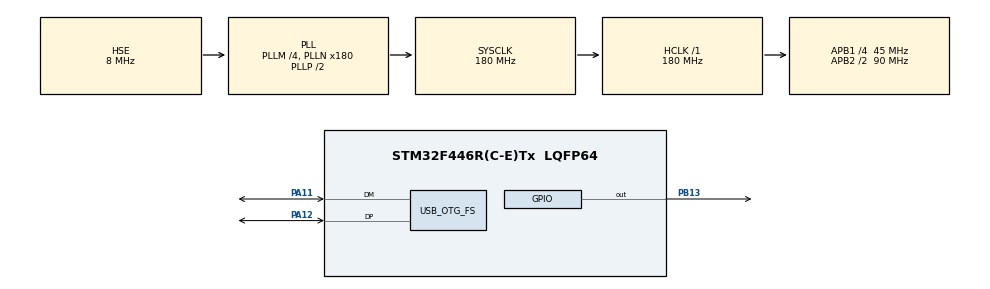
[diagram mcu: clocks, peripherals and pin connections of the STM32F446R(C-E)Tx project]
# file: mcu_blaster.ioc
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Mcu.Family=STM32F4
USB_DEVICE.CLASS_NAME_FS=CDC
USB_DEVICE.USBD_LPM_ENABLED-CDC_FS=0
PH0-OSC_IN.Signal=RCC_OSC_IN
RCC.CortexFreq_Value=180000000
USB_DEVICE.VirtualModeFS=Cdc_FS
USB_DEVICE.PID_CDC_FS=0x6001
PA11.Mode=Device_Only
USB_DEVICE.VirtualMode-CDC_FS=Cdc
RCC.APB1CLKDivider=RCC_HCLK_DIV4
PB13.Signal=GPIO_Output
RCC.SYSCLKSource=RCC_SYSCLKSOURCE_PLLCLK
ProjectManager.StackSize=0x2000
PA12.Signal=USB_OTG_FS_DP
ProjectManager.TargetToolchain=STM32CubeIDE
USB_DEVICE.PRODUCT_STRING_CDC_FS=USB-Blaster
RCC.HCLKFreq_Value=180000000
VP_USB_DEVICE_VS_USB_DEVICE_CDC_FS.Mode=CDC_FS
RCC.APB2TimFreq_Value=180000000
RCC.USBFreq_Value=48000000
RCC.AHBFreq_Value=180000000
PH0-OSC_IN.Mode=HSE-External-Oscillator
RCC.USBCLockSelection=RCC_CLK48CLKSOURCE_PLLSAIP
RCC.HSE_VALUE=8000000
board=custom
RCC.VCOOutputFreq_Value=360000000
RCC.APB2Freq_Value=90000000
USB_DEVICE.MANUFACTURER_STRING-CDC_FS=Altera
PH1-OSC_OUT.Signal=RCC_OSC_OUT
USB_DEVICE.VID-CDC_FS=0x09FB
Mcu.Name=STM32F446R(C-E)Tx
PH1-OSC_OUT.Mode=HSE-External-Oscillator
RCC.SYSCLKFreq_VALUE=180000000
Mcu.Package=LQFP64
PA12.Mode=Device_Only
NVIC.OTG_FS_IRQn=true\:0\:0\:false\:false\:true\:false\:true
PA11.Signal=USB_OTG_FS_DM
USB_OTG_FS.VirtualMode=Device_Only
ProjectManager.HeapSize=0x1000
RCC.PLLSAIN=96
RCC.PLLSAIM=4
RCC.PLLSAIP=RCC_PLLSAIP_DIV4
RCC.PLLQ=8
NVIC.PriorityGroup=NVIC_PRIORITYGROUP_4
RCC.APB2CLKDivider=RCC_HCLK_DIV2
USB_DEVICE.USBD_SELF_POWERED-CDC_FS=0
RCC.PLLM=4
RCC.PLLN=180
RCC.APB1TimFreq_Value=90000000
RCC.APB1Freq_Value=45000000

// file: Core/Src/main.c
/* USER CODE BEGIN Header */
/**
  ******************************************************************************
  * @file           : main.c
  * @brief          : Main program body
  ******************************************************************************
  * @attention
  *
  * <h2><center>&copy; Copyright (c) 2021 STMicroelectronics.
  * All rights reserved.</center></h2>
  *
  * This software component is licensed by ST under BSD 3-Clause license,
  * the "License"; You may not use this file except in compliance with the
  * License. You may obtain a copy of the License at:
  *                        opensource.org/licenses/BSD-3-Clause
  *
  ******************************************************************************
  */
/* USER CODE END Header */
#include "main.h"
#include "usb_device.h"

void SystemClock_Config(void);
static void MX_GPIO_Init(void);

int main(void)
{

  /* MCU Configuration--------------------------------------------------------*/

  /* Reset of all peripherals, Initializes the Flash interface and the Systick. */
  HAL_Init();

  /* Configure the system clock */
  SystemClock_Config();

  /* Initialize all configured peripherals */
  MX_GPIO_Init();
  MX_USB_DEVICE_Init();

  /* Infinite loop */
  while (1)
  {

    /* USER CODE BEGIN 3 */
	  HAL_GPIO_WritePin(GPIOB, GPIO_PIN_13, GPIO_PIN_RESET);
	  HAL_Delay(100);
	  HAL_GPIO_WritePin(GPIOB, GPIO_PIN_13, GPIO_PIN_SET);
	  HAL_Delay(100);
  }
  /* USER CODE END 3 */
}

void SystemClock_Config(void)
{
  RCC_OscInitTypeDef RCC_OscInitStruct = {0};
  RCC_ClkInitTypeDef RCC_ClkInitStruct = {0};
  RCC_PeriphCLKInitTypeDef PeriphClkInitStruct = {0};

  /** Configure the main internal regulator output voltage
  */
  __HAL_RCC_PWR_CLK_ENABLE();
  __HAL_PWR_VOLTAGESCALING_CONFIG(PWR_REGULATOR_VOLTAGE_SCALE1);
  /** Initializes the RCC Oscillators according to the specified parameters
  * in the RCC_OscInitTypeDef structure.
  */
  RCC_OscInitStruct.OscillatorType = RCC_OSCILLATORTYPE_HSE;
  RCC_OscInitStruct.HSEState = RCC_HSE_ON;
  RCC_OscInitStruct.PLL.PLLState = RCC_PLL_ON;
  RCC_OscInitStruct.PLL.PLLSource = RCC_PLLSOURCE_HSE;
  RCC_OscInitStruct.PLL.PLLM = 4;
  RCC_OscInitStruct.PLL.PLLN = 180;
  RCC_OscInitStruct.PLL.PLLP = RCC_PLLP_DIV2;
  RCC_OscInitStruct.PLL.PLLQ = 8;
  RCC_OscInitStruct.PLL.PLLR = 2;
  if (HAL_RCC_OscConfig(&RCC_OscInitStruct) != HAL_OK)
  {
    Error_Handler();
  }
  /** Activate the Over-Drive mode
  */
  if (HAL_PWREx_EnableOverDrive() != HAL_OK)
  {
    Error_Handler();
  }
  /** Initializes the CPU, AHB and APB buses clocks
  */
  RCC_ClkInitStruct.ClockType = RCC_CLOCKTYPE_HCLK|RCC_CLOCKTYPE_SYSCLK
                              |RCC_CLOCKTYPE_PCLK1|RCC_CLOCKTYPE_PCLK2;
  RCC_ClkInitStruct.SYSCLKSource = RCC_SYSCLKSOURCE_PLLCLK;
  RCC_ClkInitStruct.AHBCLKDivider = RCC_SYSCLK_DIV1;
  RCC_ClkInitStruct.APB1CLKDivider = RCC_HCLK_DIV4;
  RCC_ClkInitStruct.APB2CLKDivider = RCC_HCLK_DIV2;

  if (HAL_RCC_ClockConfig(&RCC_ClkInitStruct, FLASH_LATENCY_5) != HAL_OK)
  {
    Error_Handler();
  }
  PeriphClkInitStruct.PeriphClockSelection = RCC_PERIPHCLK_CLK48;
  PeriphClkInitStruct.PLLSAI.PLLSAIM = 4;
  PeriphClkInitStruct.PLLSAI.PLLSAIN = 96;
  PeriphClkInitStruct.PLLSAI.PLLSAIQ = 2;
  PeriphClkInitStruct.PLLSAI.PLLSAIP = RCC_PLLSAIP_DIV4;
  PeriphClkInitStruct.PLLSAIDivQ = 1;
  PeriphClkInitStruct.Clk48ClockSelection = RCC_CLK48CLKSOURCE_PLLSAIP;
  if (HAL_RCCEx_PeriphCLKConfig(&PeriphClkInitStruct) != HAL_OK)
  {
    Error_Handler();
  }
}

static void MX_GPIO_Init(void)
{
  GPIO_InitTypeDef GPIO_InitStruct = {0};

  /* GPIO Ports Clock Enable */
  __HAL_RCC_GPIOH_CLK_ENABLE();
  __HAL_RCC_GPIOB_CLK_ENABLE();
  __HAL_RCC_GPIOA_CLK_ENABLE();

  /*Configure GPIO pin Output Level */
  HAL_GPIO_WritePin(GPIOB, GPIO_PIN_13, GPIO_PIN_RESET);

  /*Configure GPIO pin : PB13 */
  GPIO_InitStruct.Pin = GPIO_PIN_13;
  GPIO_InitStruct.Mode = GPIO_MODE_OUTPUT_PP;
  GPIO_InitStruct.Pull = GPIO_NOPULL;
  GPIO_InitStruct.Speed = GPIO_SPEED_FREQ_LOW;
  HAL_GPIO_Init(GPIOB, &GPIO_InitStruct);

}

void Error_Handler(void)
{
  __disable_irq();
  while (1)
  {
  }
}

/************************ (C) COPYRIGHT STMicroelectronics *****END OF FILE****/
